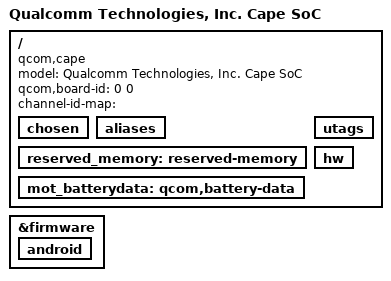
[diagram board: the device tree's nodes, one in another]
/* Copyright (c) 2022, The Linux Foundation. All rights reserved.
 *
 * This program is free software; you can redistribute it and/or modify
 * it under the terms of the GNU General Public License version 2 and
 * only version 2 as published by the Free Software Foundation.
 *
 * This program is distributed in the hope that it will be useful,
 * but WITHOUT ANY WARRANTY; without even the implied warranty of
 * MERCHANTABILITY or FITNESS FOR A PARTICULAR PURPOSE.  See the
 * GNU General Public License for more details.
 */

/dts-v1/;

#include "cape-v2.dtsi"

/ {
	model = "Qualcomm Technologies, Inc. Cape SoC";
	compatible = "qcom,cape";
	qcom,board-id = <0 0>;
	channel-id-map = "";
/*
 * Some nodes need labels assigned to appear in __symbols__
 */
	chosen: chosen { };
	aliases: aliases { };
	reserved_memory: reserved-memory { };
	mot_batterydata: qcom,battery-data { };
	utags: utags { };
	hw: hw { };
};

&reserved_memory {
	/delete-node/ ramoops_region;
};

&firmware {
	android {
		/delete-node/ fstab;
	};
};

/delete-node/ &mem_offline;
